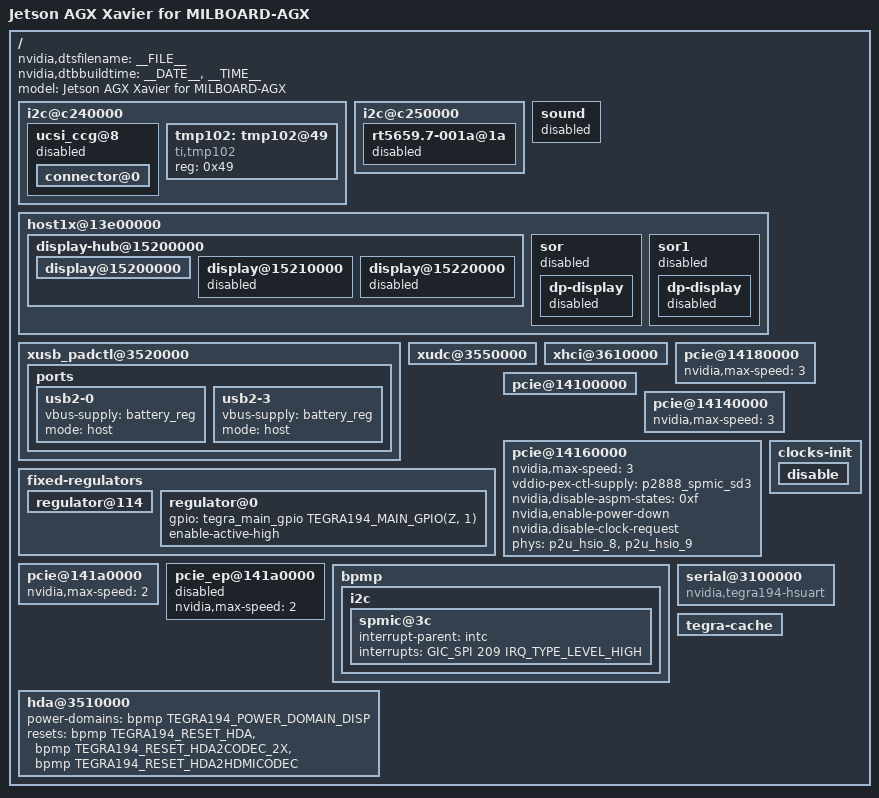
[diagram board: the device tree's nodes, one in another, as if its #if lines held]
/*
 * Top level DTS file for CVM:P2888-0001 and CVB:MILBOARD-AGX.
 *
 * Copyright (c) 2020-2022, Mist Elektronik Biyomedikal Ltd. Şti.  All rights reserved.
 *
 * This program is free software; you can redistribute it and/or modify
 * it under the terms of the GNU General Public License as published by
 * the Free Software Foundation; version 2 of the License.
 *
 * This program is distributed in the hope that it will be useful, but WITHOUT
 * ANY WARRANTY; without even the implied warranty of MERCHANTABILITY or
 * FITNESS FOR A PARTICULAR PURPOSE.  See the GNU General Public License for
 * more details.
 */
#include "common/tegra194-p2888-0001-p2822-0000-common.dtsi"
//#include "common/tegra194-p2822-camera-modules.dtsi"
#include "common/tegra194-audio-p2822-0000.dtsi"

#if defined(LINUX_VERSION) && LINUX_VERSION >= 419

/ {
	nvidia,dtsfilename = __FILE__;
	nvidia,dtbbuildtime = __DATE__, __TIME__;
	model = "Jetson AGX Xavier for MILBOARD-AGX";

	i2c@c240000 {
		ucsi_ccg@8 {
			status = "disabled";
			connector@0 {
				/delete-node/ port;
			};
		};
		tmp102: tmp102@49 { // Temperature Sensor
			compatible = "ti,tmp102";
			reg = <0x49>;
			#thermal-sensor-cells = <0>;
		};
	};

	i2c@c250000 {
		rt5659.7-001a@1a {
			status = "disabled";
		};
	};

	sound {
		status = "disabled";
	};

	host1x@13e00000 {
		display-hub@15200000 {

			display@15200000 {
				/delete-property/  extcon-cables;
				/delete-property/  extcon-cable-names;
				/delete-property/  #extcon-cells;
			};

			display@15210000 {
				status="disabled";
				/delete-property/  extcon-cables;
				/delete-property/  extcon-cable-names;
				/delete-property/  #extcon-cells;
			};

			display@15220000 {
				status="disabled";
				/delete-property/  extcon-cables;
				/delete-property/  extcon-cable-names;
				/delete-property/  #extcon-cells;
			};

		};

		sor {
			status = "disabled";
			/delete-property/  nvidia,typec-port;
			dp-display {
				status = "disabled";
			};
		};

		sor1 {
			status = "disabled";
			/delete-property/  nvidia,typec-port;
			dp-display {
				status = "disabled";
			};
		};
	};

	xusb_padctl@3520000 {

		ports {
			usb2-0 {
				status = "okay";
				vbus-supply = <&battery_reg>;
				mode = "host";
				/delete-property/ usb-role-switch;
				/delete-node/ port;
			};
			usb2-3 {
				status = "okay";
				vbus-supply = <&battery_reg>;
				mode = "host";
			};
		};
	};

	xudc@3550000 {
		phy-names = "usb2", "usb3";
		/delete-property/  extcon-cables;
		/delete-property/  extcon-cable-names;
		/delete-property/  #extcon-cells;
	};

	xhci@3610000 {
		/delete-property/  extcon-cables;
		/delete-property/  extcon-cable-names;
		/delete-property/  #extcon-cells;
	};

	/delete-node/ usb_cd;
	
	fixed-regulators {
		regulator@114 {
			/delete-property/	gpio;
			/delete-property/	enable-active-high;
		};

		regulator@0 {
			/delete-property/	regulator-always-on;
			gpio = <&tegra_main_gpio TEGRA194_MAIN_GPIO(Z, 1) 0x0>;
			enable-active-high;
		};
	};

	pcie@14180000 { // PCIe x4 (C0)
		nvidia,max-speed = <3>;
	};

	pcie@14100000 { // PCIe x1 (C1)
		status = "okay";
	};

	pcie@14140000 { // PCIe x1 (C3)
		nvidia,max-speed = <3>;
	};

	pcie@14160000 { // PCIe x2 (C4)
		status = "okay";
		nvidia,max-speed = <3>;

		vddio-pex-ctl-supply = <&p2888_spmic_sd3>;
		nvidia,disable-aspm-states = <0xf>;
		nvidia,enable-power-down;
		nvidia,disable-clock-request;

		phys = <&p2u_hsio_8>, <&p2u_hsio_9>;
		phy-names = "p2u-0", "p2u-1";
	};

	pcie@141a0000 { // PCIe x8 (C5)
		nvidia,max-speed = <2>;
	};

	pcie_ep@141a0000 {
		status = "disabled";
		nvidia,max-speed = <2>;
	};

	clocks-init {
		disable {
			/delete-property/ clocks;
		};
	};

	/* FIXME: K5.4 overrides */
	bpmp {
		i2c {
			spmic@3c {
				interrupt-parent = <&intc>;
				interrupts = <GIC_SPI 209 IRQ_TYPE_LEVEL_HIGH>;
			};
		};
	};

	hda@3510000 {
		power-domains = <&bpmp TEGRA194_POWER_DOMAIN_DISP>;
		resets = <&bpmp TEGRA194_RESET_HDA>,
		         <&bpmp TEGRA194_RESET_HDA2CODEC_2X>,
		         <&bpmp TEGRA194_RESET_HDA2HDMICODEC>;
		reset-names = "hda", "hda2codec_2x", "hda2hdmi";
	};

	serial@3100000 {
		compatible = "nvidia,tegra194-hsuart";
	};

	tegra-cache {
		status = "okay";
	};
};

#endif
